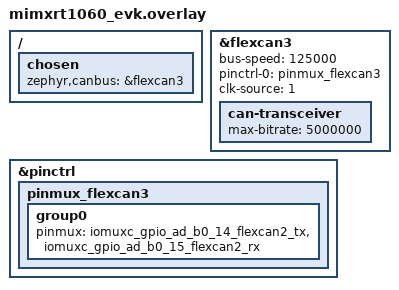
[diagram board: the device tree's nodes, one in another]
/delete-node/ &flexcan2;

/ {
	chosen {
		zephyr,canbus = &flexcan3;
	};
};

&flexcan3 {
	status = "okay";
	bus-speed = <125000>;
	pinctrl-0 = <&pinmux_flexcan3>;
	clk-source = <1>;
	pinctrl-names = "default";

	can-transceiver {
		max-bitrate = <5000000>;
	};
};


/* Option 1 */
&pinctrl {
pinmux_flexcan3: pinmux_flexcan3 {
	group0 {
		pinmux = <&iomuxc_gpio_ad_b0_14_flexcan2_tx>,
			<&iomuxc_gpio_ad_b0_15_flexcan2_rx>;
			};
	};
};

